# ior7f701503 register map
Registers are 8-bit, access not given, no defined reset value unless marked. A register's access mark holds for its fields unless they carry their own. Addresses are absolute; registers are grouped by the start of their names; [hi:lo] are bit positions; {n}, {i} and the like mark numbered series.

## SFR (part 3 of 4)
0xFFD0903C RSCAN1TMDF13 32-bit
0xFFD0903C RSCAN1TMDF13L 16-bit
0xFFD0903C RSCAN1TMDF13LL
0xFFD0903D RSCAN1TMDF13LH
0xFFD0903E RSCAN1TMDF13H 16-bit
0xFFD0903E RSCAN1TMDF13HL
0xFFD0903F RSCAN1TMDF13HH
0xFFD0904C RSCAN1TMDF14 32-bit
0xFFD0904C RSCAN1TMDF14L 16-bit
0xFFD0904C RSCAN1TMDF14LL
0xFFD0904D RSCAN1TMDF14LH
0xFFD0904E RSCAN1TMDF14H 16-bit
0xFFD0904E RSCAN1TMDF14HL
0xFFD0904F RSCAN1TMDF14HH
0xFFD0905C RSCAN1TMDF15 32-bit
0xFFD0905C RSCAN1TMDF15L 16-bit
0xFFD0905C RSCAN1TMDF15LL
0xFFD0905D RSCAN1TMDF15LH
0xFFD0905E RSCAN1TMDF15H 16-bit
0xFFD0905E RSCAN1TMDF15HL
0xFFD0905F RSCAN1TMDF15HH
{0xFFD08F6C+0x10*i} RSCAN1TMDF{i} 32-bit (i=16..19)
{0xFFD08F6C+0x10*i} RSCAN1TMDF{i}L 16-bit (i=16..19)
{0xFFD08F6C+0x10*i} RSCAN1TMDF{i}LL (i=16..19)
{0xFFD08F6D+0x10*i} RSCAN1TMDF{i}LH (i=16..19)
{0xFFD08F6E+0x10*i} RSCAN1TMDF{i}H 16-bit (i=16..19)
{0xFFD08F6E+0x10*i} RSCAN1TMDF{i}HL (i=16..19)
{0xFFD08F6F+0x10*i} RSCAN1TMDF{i}HH (i=16..19)
{0xFFD09008+0x10*i} RSCAN1TMDF{i:03} 32-bit (i=10..12)
{0xFFD09008+0x10*i} RSCAN1TMDF{i:03}L 16-bit (i=10..12)
{0xFFD09008+0x10*i} RSCAN1TMDF{i:03}LL (i=10..12)
{0xFFD09009+0x10*i} RSCAN1TMDF{i:03}LH (i=10..12)
{0xFFD0900A+0x10*i} RSCAN1TMDF{i:03}H 16-bit (i=10..12)
{0xFFD0900A+0x10*i} RSCAN1TMDF{i:03}HL (i=10..12)
{0xFFD0900B+0x10*i} RSCAN1TMDF{i:03}HH (i=10..12)
{0xFFD089CC+0x10*i} RSCAN1TMDF{i} 32-bit (i=110..115)
{0xFFD089CC+0x10*i} RSCAN1TMDF{i}L 16-bit (i=110..115)
{0xFFD089CC+0x10*i} RSCAN1TMDF{i}LL (i=110..115)
{0xFFD089CD+0x10*i} RSCAN1TMDF{i}LH (i=110..115)
{0xFFD089CE+0x10*i} RSCAN1TMDF{i}H 16-bit (i=110..115)
{0xFFD089CE+0x10*i} RSCAN1TMDF{i}HL (i=110..115)
{0xFFD089CF+0x10*i} RSCAN1TMDF{i}HH (i=110..115)
0xFFD090D8 RSCAN1TMDF013 32-bit
0xFFD090D8 RSCAN1TMDF013L 16-bit
0xFFD090D8 RSCAN1TMDF013LL
0xFFD090D9 RSCAN1TMDF013LH
0xFFD090DA RSCAN1TMDF013H 16-bit
0xFFD090DA RSCAN1TMDF013HL
0xFFD090DB RSCAN1TMDF013HH
0xFFD090E8 RSCAN1TMDF014 32-bit
0xFFD090E8 RSCAN1TMDF014L 16-bit
0xFFD090E8 RSCAN1TMDF014LL
0xFFD090E9 RSCAN1TMDF014LH
0xFFD090EA RSCAN1TMDF014H 16-bit
0xFFD090EA RSCAN1TMDF014HL
0xFFD090EB RSCAN1TMDF014HH
0xFFD090F8 RSCAN1TMDF015 32-bit
0xFFD090F8 RSCAN1TMDF015L 16-bit
0xFFD090F8 RSCAN1TMDF015LL
0xFFD090F9 RSCAN1TMDF015LH
0xFFD090FA RSCAN1TMDF015H 16-bit
0xFFD090FA RSCAN1TMDF015HL
0xFFD090FB RSCAN1TMDF015HH
0xFFD09800 RSCAN1THLACC6 32-bit ro
0xFFD09800 RSCAN1THLACC6L 16-bit ro
0xFFD09800 RSCAN1THLACC6LL ro
0xFFD09801 RSCAN1THLACC6LH ro
{0xFFD09900+4i} RSCAN1RPGACC{i} 32-bit (i=0..63)
{0xFFD09900+4i} RSCAN1RPGACC{i}L 16-bit (i=0..63)
{0xFFD09900+4i} RSCAN1RPGACC{i}LL (i=0..63)
{0xFFD09901+4i} RSCAN1RPGACC{i}LH (i=0..63)
{0xFFD09902+4i} RSCAN1RPGACC{i}H 16-bit (i=0..63)
{0xFFD09902+4i} RSCAN1RPGACC{i}HL (i=0..63)
{0xFFD09903+4i} RSCAN1RPGACC{i}HH (i=0..63)
{0xFFD6D000+4i} ADCA1VCR{i:02} 32-bit (i=0..23)
{0xFFD6D000+4i} ADCA1VCR{i:02}L 16-bit (i=0..23)
{0xFFD6D000+4i} ADCA1VCR{i:02}LL (i=0..23)
{0xFFD6D001+4i} ADCA1VCR{i:02}LH (i=0..23)
0xFFD6D0F4 ADCA1PWDVCR 32-bit ro
0xFFD6D0F4 ADCA1PWDVCRL 16-bit ro
0xFFD6D0F4 ADCA1PWDVCRLL ro
0xFFD6D0F5 ADCA1PWDVCRLH ro
0xFFD6D100 ADCA1DR00 32-bit ro
0xFFD6D100 ADCA1DR00L 16-bit ro
0xFFD6D102 ADCA1DR00H 16-bit ro
0xFFD6D104 ADCA1DR02 32-bit ro
0xFFD6D104 ADCA1DR02L 16-bit ro
0xFFD6D106 ADCA1DR02H 16-bit ro
0xFFD6D108 ADCA1DR04 32-bit ro
0xFFD6D108 ADCA1DR04L 16-bit ro
0xFFD6D10A ADCA1DR04H 16-bit ro
0xFFD6D10C ADCA1DR06 32-bit ro
0xFFD6D10C ADCA1DR06L 16-bit ro
0xFFD6D10E ADCA1DR06H 16-bit ro
0xFFD6D110 ADCA1DR08 32-bit ro
0xFFD6D110 ADCA1DR08L 16-bit ro
0xFFD6D112 ADCA1DR08H 16-bit ro
0xFFD6D114 ADCA1DR10 32-bit ro
0xFFD6D114 ADCA1DR10L 16-bit ro
0xFFD6D116 ADCA1DR10H 16-bit ro
0xFFD6D118 ADCA1DR12 32-bit ro
0xFFD6D118 ADCA1DR12L 16-bit ro
0xFFD6D11A ADCA1DR12H 16-bit ro
0xFFD6D11C ADCA1DR14 32-bit ro
0xFFD6D11C ADCA1DR14L 16-bit ro
0xFFD6D11E ADCA1DR14H 16-bit ro
0xFFD6D120 ADCA1DR16 32-bit ro
0xFFD6D120 ADCA1DR16L 16-bit ro
0xFFD6D122 ADCA1DR16H 16-bit ro
0xFFD6D124 ADCA1DR18 32-bit ro
0xFFD6D124 ADCA1DR18L 16-bit ro
0xFFD6D126 ADCA1DR18H 16-bit ro
0xFFD6D128 ADCA1DR20 32-bit ro
0xFFD6D128 ADCA1DR20L 16-bit ro
0xFFD6D12A ADCA1DR20H 16-bit ro
0xFFD6D12C ADCA1DR22 32-bit ro
0xFFD6D12C ADCA1DR22L 16-bit ro
0xFFD6D12E ADCA1DR22H 16-bit ro
0xFFD6D178 ADCA1PWDTSNDR 32-bit ro
0xFFD6D17A ADCA1PWDTSNDRH 16-bit ro
{0xFFD6D200+4i} ADCA1DIR{i:02} 32-bit ro (i=0..23)
0xFFD6D2F4 ADCA1PWDDIR 32-bit ro
0xFFD6D300 ADCA1ADHALTR 32-bit wo
0xFFD6D300 ADCA1ADHALTRL 16-bit wo
0xFFD6D300 ADCA1ADHALTRLL wo
0xFFD6D304 ADCA1ADCR 32-bit
0xFFD6D304 ADCA1ADCRL 16-bit
0xFFD6D304 ADCA1ADCRLL
0xFFD6D308 ADCA1SGSTR 32-bit ro
0xFFD6D308 ADCA1SGSTRL 16-bit ro
0xFFD6D334 ADCA1SFTCR 32-bit
0xFFD6D334 ADCA1SFTCRL 16-bit
0xFFD6D334 ADCA1SFTCRLL
{0xFFD6D338+4i} ADCA1ULLMTBR{i} 32-bit (i=0..2)
{0xFFD6D338+4i} ADCA1ULLMTBR{i}L 16-bit (i=0..2)
{0xFFD6D33A+4i} ADCA1ULLMTBR{i}H 16-bit (i=0..2)
0xFFD6D344 ADCA1ECR 32-bit wo
0xFFD6D344 ADCA1ECRL 16-bit wo
0xFFD6D344 ADCA1ECRLL wo
0xFFD6D348 ADCA1ULER 32-bit ro
0xFFD6D348 ADCA1ULERL 16-bit ro
0xFFD6D348 ADCA1ULERLL ro
0xFFD6D349 ADCA1ULERLH ro
0xFFD6D34C ADCA1OWER 32-bit ro
0xFFD6D34C ADCA1OWERL 16-bit ro
0xFFD6D34C ADCA1OWERLL ro
0xFFD6D350 ADCA1DGCTL0 32-bit
0xFFD6D350 ADCA1DGCTL0L 16-bit
0xFFD6D350 ADCA1DGCTL0LL
0xFFD6D354 ADCA1DGCTL1 32-bit
0xFFD6D354 ADCA1DGCTL1L 16-bit
0xFFD6D358 ADCA1PDCTL1 32-bit
0xFFD6D358 ADCA1PDCTL1L 16-bit
0xFFD6D35C ADCA1PDCTL2 32-bit
0xFFD6D35C ADCA1PDCTL2L 16-bit
0xFFD6D35C ADCA1PDCTL2LL
0xFFD6D380 ADCA1SMPCR 32-bit
0xFFD6D380 ADCA1SMPCRL 16-bit
0xFFD6D380 ADCA1SMPCRLL
0xFFD6D388 ADCA1EMU
{0xFFD6D400+0x40*i} ADCA1SGSTCR{i} 32-bit wo (i=1..3)
{0xFFD6D400+0x40*i} ADCA1SGSTCR{i}L 16-bit wo (i=1..3)
{0xFFD6D400+0x40*i} ADCA1SGSTCR{i}LL wo (i=1..3)
{0xFFD6D408+0x40*i} ADCA1SGCR{i} 32-bit (i=1..3)
{0xFFD6D408+0x40*i} ADCA1SGCR{i}L 16-bit (i=1..3)
{0xFFD6D408+0x40*i} ADCA1SGCR{i}LL (i=1..3)
{0xFFD6D40C+0x40*i} ADCA1SGVCSP{i} 32-bit (i=1..3)
{0xFFD6D40C+0x40*i} ADCA1SGVCSP{i}L 16-bit (i=1..3)
{0xFFD6D40C+0x40*i} ADCA1SGVCSP{i}LL (i=1..3)
{0xFFD6D410+0x40*i} ADCA1SGVCEP{i} 32-bit (i=1..3)
{0xFFD6D410+0x40*i} ADCA1SGVCEP{i}L 16-bit (i=1..3)
{0xFFD6D410+0x40*i} ADCA1SGVCEP{i}LL (i=1..3)
{0xFFD6D414+0x40*i} ADCA1SGMCYCR{i} 32-bit (i=1..3)
{0xFFD6D414+0x40*i} ADCA1SGMCYCR{i}L 16-bit (i=1..3)
{0xFFD6D414+0x40*i} ADCA1SGMCYCR{i}LL (i=1..3)
{0xFFD6D418+0x40*i} ADCA1SGSEFCR{i} 32-bit wo (i=1..3)
{0xFFD6D418+0x40*i} ADCA1SGSEFCR{i}L 16-bit wo (i=1..3)
{0xFFD6D418+0x40*i} ADCA1SGSEFCR{i}LL wo (i=1..3)
{0xFFD6D41C+0x40*i} ADCA1SGTSEL{i} 32-bit (i=1..3)
{0xFFD6D41C+0x40*i} ADCA1SGTSEL{i}L 16-bit (i=1..3)
0xFFD6D508 ADCA1PWDSGCR 32-bit
0xFFD6D508 ADCA1PWDSGCRL 16-bit
0xFFD6D508 ADCA1PWDSGCRLL
0xFFD6D518 ADCA1PWDSGSEFCR 32-bit wo
0xFFD6D518 ADCA1PWDSGSEFCRL 16-bit wo
0xFFD6D518 ADCA1PWDSGSEFCRLL wo
0xFFD6E000 ETNB0CCC 32-bit
0xFFD6E000 ETNB0CCCL 16-bit
0xFFD6E000 ETNB0CCCLL
0xFFD6E001 ETNB0CCCLH
0xFFD6E002 ETNB0CCCH 16-bit
0xFFD6E002 ETNB0CCCHL
0xFFD6E003 ETNB0CCCHH
0xFFD6E004 ETNB0DBAT 32-bit
0xFFD6E008 ETNB0DLR 32-bit
0xFFD6E00C ETNB0CSR 32-bit ro
{0xFFD6E010+4i} ETNB0CDAR{i} 32-bit ro (i=0..21)
0xFFD6E088 ETNB0ESR 32-bit ro
0xFFD6E090 ETNB0RCR 32-bit
{0xFFD6E094+4i} ETNB0RQC{i} 32-bit (i=0..4)
{0xFFD6E094+4i} ETNB0RQC{i}L 16-bit (i=0..4)
{0xFFD6E094+4i} ETNB0RQC{i}LL (i=0..4)
{0xFFD6E095+4i} ETNB0RQC{i}LH (i=0..4)
{0xFFD6E096+4i} ETNB0RQC{i}H 16-bit (i=0..4)
{0xFFD6E096+4i} ETNB0RQC{i}HL (i=0..4)
{0xFFD6E097+4i} ETNB0RQC{i}HH (i=0..4)
0xFFD6E0B0 ETNB0RPC 32-bit
0xFFD6E0BC ETNB0UFCW 32-bit
0xFFD6E0C0 ETNB0UFCS 32-bit
{0xFFD6E0C4+4i} ETNB0UFCV{i} 32-bit ro (i=0..4)
{0xFFD6E0E0+4i} ETNB0UFCD{i} 32-bit (i=0..4)
{0xFFD6E0E0+4i} ETNB0UFCD{i}L 16-bit (i=0..4)
{0xFFD6E0E0+4i} ETNB0UFCD{i}LL (i=0..4)
{0xFFD6E0E1+4i} ETNB0UFCD{i}LH (i=0..4)
{0xFFD6E0E2+4i} ETNB0UFCD{i}H 16-bit (i=0..4)
{0xFFD6E0E2+4i} ETNB0UFCD{i}HL (i=0..4)
{0xFFD6E0E3+4i} ETNB0UFCD{i}HH (i=0..4)
0xFFD6E0FC ETNB0SFO 32-bit
{0xFFD6E100+4i} ETNB0SFP{i} 32-bit (i=0..31)
0xFFD6E1C0 ETNB0SFM0 32-bit
0xFFD6E1C4 ETNB0SFM1 32-bit
0xFFD6E300 ETNB0TGC 32-bit
0xFFD6E304 ETNB0TCCR 32-bit
0xFFD6E304 ETNB0TCCRL 16-bit
0xFFD6E304 ETNB0TCCRLL
0xFFD6E305 ETNB0TCCRLH
0xFFD6E306 ETNB0TCCRH 16-bit
0xFFD6E306 ETNB0TCCRHL
0xFFD6E308 ETNB0TSR 32-bit ro
{0xFFD6E310+4i} ETNB0TFA{i} 32-bit ro (i=0..2)
0xFFD6E320 ETNB0CIVR0 32-bit
0xFFD6E324 ETNB0CIVR1 32-bit
0xFFD6E328 ETNB0CDVR0 32-bit
0xFFD6E32C ETNB0CDVR1 32-bit
0xFFD6E330 ETNB0CUL0 32-bit
0xFFD6E334 ETNB0CUL1 32-bit
0xFFD6E338 ETNB0CLL0 32-bit
0xFFD6E33C ETNB0CLL1 32-bit
0xFFD6E350 ETNB0DIC 32-bit
0xFFD6E354 ETNB0DIS 32-bit
0xFFD6E358 ETNB0EIC 32-bit
0xFFD6E35C ETNB0EIS 32-bit
{0xFFD6E360+8i} ETNB0RIC{i} 32-bit (i=0..2)
{0xFFD6E364+8i} ETNB0RIS{i} 32-bit (i=0..2)
0xFFD6E378 ETNB0TIC 32-bit
0xFFD6E37C ETNB0TIS 32-bit
0xFFD6E380 ETNB0ISS 32-bit ro
0xFFD6E390 ETNB0GCCR 32-bit
0xFFD6E390 ETNB0GCCRL 16-bit
0xFFD6E390 ETNB0GCCRLL
0xFFD6E391 ETNB0GCCRLH
0xFFD6E394 ETNB0GMTT 32-bit
0xFFD6E398 ETNB0GPTC 32-bit
0xFFD6E39C ETNB0GTI 32-bit
{0xFFD6E3A0+4i} ETNB0GTO{i} 32-bit (i=0..2)
0xFFD6E3AC ETNB0GIC 32-bit
0xFFD6E3B0 ETNB0GIS 32-bit
0xFFD6E3B4 ETNB0GCPT 32-bit ro
{0xFFD6E3B8+4i} ETNB0GCT{i} 32-bit ro (i=0..2)
0xFFD6E500 ETNB0ECMR 32-bit
0xFFD6E508 ETNB0RFLR 32-bit
0xFFD6E510 ETNB0ECSR 32-bit
0xFFD6E518 ETNB0ECSIPR 32-bit
0xFFD6E520 ETNB0PIR 32-bit
0xFFD6E528 ETNB0PLSR 32-bit ro
0xFFD6E554 ETNB0APFTP 32-bit
0xFFD6E558 ETNB0MPR 32-bit
0xFFD6E55C ETNB0PFTCR 32-bit
0xFFD6E560 ETNB0PFRCR 32-bit
0xFFD6E5B0 ETNB0GECMR 32-bit
0xFFD6E5C0 ETNB0MAHR 32-bit
0xFFD6E5C8 ETNB0MALR 32-bit
0xFFD6E700 ETNB0TROCR 32-bit
0xFFD6E708 ETNB0CDCR 32-bit
0xFFD6E710 ETNB0LCCR 32-bit
0xFFD6E740 ETNB0CEFCR 32-bit
0xFFD6E748 ETNB0FRECR 32-bit
0xFFD6E750 ETNB0TSFRCR 32-bit
0xFFD6E758 ETNB0TLFRCR 32-bit
0xFFD6E760 ETNB0RFCR 32-bit
0xFFD6E768 ETNB0CERCR 32-bit
0xFFD6E770 ETNB0CEECR 32-bit
0xFFD6E778 ETNB0MAFCR 32-bit
0xFFD6F000 ETNB0IFCTL 32-bit
{0xFFD70000+0x100*i} OSTM{i}CMP 32-bit (i=0..4)
{0xFFD70004+0x100*i} OSTM{i}CNT 32-bit ro (i=0..4)
{0xFFD70010+0x100*i} OSTM{i}TE ro (i=0..4)
{0xFFD70014+0x100*i} OSTM{i}TS wo (i=0..4)
{0xFFD70018+0x100*i} OSTM{i}TT wo (i=0..4)
{0xFFD70020+0x100*i} OSTM{i}CTL (i=0..4)
{0xFFD70024+0x100*i} OSTM{i}EMU (i=0..4)
{0xFFD70B00+0x100*i} OSTM{i}CMP 32-bit (i=5..9)
{0xFFD70B04+0x100*i} OSTM{i}CNT 32-bit ro (i=5..9)
{0xFFD70B10+0x100*i} OSTM{i}TE ro (i=5..9)
{0xFFD70B14+0x100*i} OSTM{i}TS wo (i=5..9)
{0xFFD70B18+0x100*i} OSTM{i}TT wo (i=5..9)
{0xFFD70B20+0x100*i} OSTM{i}CTL (i=5..9)
{0xFFD70B24+0x100*i} OSTM{i}EMU (i=5..9)
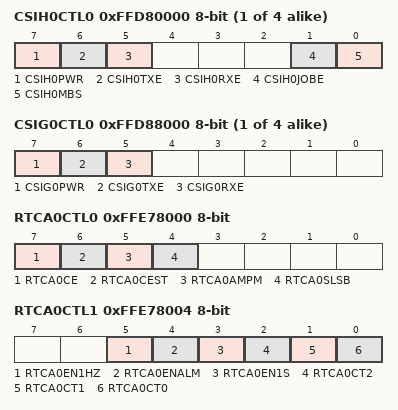
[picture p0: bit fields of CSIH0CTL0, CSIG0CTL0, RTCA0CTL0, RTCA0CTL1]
{0xFFD80000+0x2000*i} CSIH{i}CTL0 (i=0..3)
  [7] CSIH{i}PWR, [6] CSIH{i}TXE, [5] CSIH{i}RXE, [1] CSIH{i}JOBE, [0] CSIH{i}MBS
{0xFFD80004+0x2000*i} CSIH{i}STR0 32-bit ro (i=0..3)
{0xFFD80008+0x2000*i} CSIH{i}STCR0 16-bit (i=0..3)
{0xFFD80010+0x2000*i} CSIH{i}CTL1 32-bit (i=0..3)
{0xFFD80014+0x2000*i} CSIH{i}CTL2 16-bit (i=0..3)
{0xFFD80018+0x2000*i} CSIH{i}EMU (i=0..3)
  [7] CSIH{i}SVSDIS
{0xFFD81000+0x2000*i} CSIH{i}MCTL1 32-bit (i=0..3)
{0xFFD81004+0x2000*i} CSIH{i}MCTL2 32-bit (i=0..3)
{0xFFD81008+0x2000*i} CSIH{i}TX0W 32-bit (i=0..3)
{0xFFD8100C+0x2000*i} CSIH{i}TX0H 16-bit (i=0..3)
{0xFFD81010+0x2000*i} CSIH{i}RX0W 32-bit ro (i=0..3)
{0xFFD81014+0x2000*i} CSIH{i}RX0H 16-bit ro (i=0..3)
{0xFFD81018+0x2000*i} CSIH{i}MRWP0 32-bit (i=0..3)
{0xFFD81040+0x2000*i} CSIH{i}MCTL0 16-bit (i=0..3)
{0xFFD81044+4i} CSIH0CFG{i} 32-bit (i=0..7)
{0xFFD81068+0x2000*i} CSIH{i}BRS0 16-bit (i=0..3)
{0xFFD8106C+0x2000*i} CSIH{i}BRS1 16-bit (i=0..3)
{0xFFD81070+0x2000*i} CSIH{i}BRS2 16-bit (i=0..3)
{0xFFD81074+0x2000*i} CSIH{i}BRS3 16-bit (i=0..3)
{0xFFD83044+4i} CSIH1CFG{i} 32-bit (i=0..5)
{0xFFD85044+4i} CSIH2CFG{i} 32-bit (i=0..5)
{0xFFD87044+4i} CSIH3CFG{i} 32-bit (i=0..3)
{0xFFD88000+0x2000*i} CSIG{i}CTL0 (i=0..3)
  [7] CSIG{i}PWR, [6] CSIG{i}TXE, [5] CSIG{i}RXE
{0xFFD88004+0x2000*i} CSIG{i}STR0 32-bit ro (i=0..3)
{0xFFD88008+0x2000*i} CSIG{i}STCR0 16-bit (i=0..3)
{0xFFD88010+0x2000*i} CSIG{i}CTL1 32-bit (i=0..3)
{0xFFD88014+0x2000*i} CSIG{i}CTL2 16-bit (i=0..3)
{0xFFD88018+0x2000*i} CSIG{i}EMU (i=0..3)
  [7] CSIG{i}SVSDIS
{0xFFD89000+0x2000*i} CSIG{i}BCTL0 (i=0..3)
  [0] CSIG{i}SCE
{0xFFD89004+0x2000*i} CSIG{i}TX0W 32-bit (i=0..3)
{0xFFD89008+0x2000*i} CSIG{i}TX0H 16-bit (i=0..3)
{0xFFD8900C+0x2000*i} CSIG{i}RX0 16-bit ro (i=0..3)
{0xFFD89010+0x2000*i} CSIG{i}CFG0 32-bit (i=0..3)
0xFFDD0004 PIC0SST wo
0xFFDD0010 PIC0SSER0 16-bit
0xFFDD0018 PIC0SSER2 16-bit
0xFFDD0080 PIC0HIZCEN0
{0xFFDCFA50+4i} PIC0ADTEN{i} 16-bit (i=400..402)
{0xFFDCFDA0+4i} PIC0REG{i} 32-bit (i=200..203)
0xFFDD00E8 PIC0REG30 32-bit
0xFFDD00EC PIC0REG31 32-bit
{0xFFDDD000+4i} FSGD02PROT{i} 32-bit (i=0..10)
{0xFFDDD000+4i} FSGD02PROT{i}L 16-bit (i=0..10)
{0xFFDDD000+4i} FSGD02PROT{i}LL (i=0..10)
{0xFFDDD001+4i} FSGD02PROT{i}LH (i=0..10)
{0xFFDDD002+4i} FSGD02PROT{i}H 16-bit (i=0..10)
{0xFFDDD002+4i} FSGD02PROT{i}HL (i=0..10)
{0xFFDDD003+4i} FSGD02PROT{i}HH (i=0..10)
0xFFDDD040 ERRSLV02CTL 32-bit wo
0xFFDDD040 ERRSLV02CTLL 16-bit wo
0xFFDDD040 ERRSLV02CTLLL wo
0xFFDDD044 ERRSLV02STAT 32-bit ro
0xFFDDD044 ERRSLV02STATL 16-bit ro
0xFFDDD044 ERRSLV02STATLL ro
0xFFDDD04C ERRSLV02TYPE 32-bit ro
0xFFDDD04C ERRSLV02TYPEL 16-bit ro
{0xFFE20000+4i} TAUD0CDR{i} 16-bit (i=0..15)
0xFFE20040 TAUD0TOL 16-bit
0xFFE20044 TAUD0RDT 16-bit wo
0xFFE20048 TAUD0RSF 16-bit ro
0xFFE2004C TAUD0TRO 16-bit
0xFFE20050 TAUD0TME 16-bit
0xFFE20054 TAUD0TDL 16-bit
0xFFE20058 TAUD0TO 16-bit
0xFFE2005C TAUD0TOE 16-bit
{0xFFE20080+4i} TAUD0CNT{i} 16-bit ro (i=0..15)
{0xFFE200C0+4i} TAUD0CMUR{i} (i=0..15)
{0xFFE20140+4i} TAUD0CSR{i} ro (i=0..15)
{0xFFE20180+4i} TAUD0CSC{i} wo (i=0..15)
0xFFE201C0 TAUD0TE 16-bit ro
0xFFE201C4 TAUD0TS 16-bit wo
0xFFE201C8 TAUD0TT 16-bit wo
{0xFFE20200+4i} TAUD0CMOR{i} 16-bit (i=0..15)
0xFFE20240 TAUD0TPS 16-bit
0xFFE20244 TAUD0BRS
0xFFE20248 TAUD0TOM 16-bit
0xFFE2024C TAUD0TOC 16-bit
0xFFE20250 TAUD0TDE 16-bit
0xFFE20254 TAUD0TDM 16-bit
0xFFE20258 TAUD0TRE 16-bit
0xFFE2025C TAUD0TRC 16-bit
0xFFE20260 TAUD0RDE 16-bit
0xFFE20264 TAUD0RDM 16-bit
0xFFE20268 TAUD0RDS 16-bit
0xFFE2026C TAUD0RDC 16-bit
0xFFE20290 TAUD0EMU
{0xFFE30000+4i} TAUB0CDR{i} 16-bit (i=0..15)
0xFFE30040 TAUB0TOL 16-bit
0xFFE30044 TAUB0RDT 16-bit wo
0xFFE30048 TAUB0RSF 16-bit ro
0xFFE30054 TAUB0TDL 16-bit
0xFFE30058 TAUB0TO 16-bit
0xFFE3005C TAUB0TOE 16-bit
{0xFFE30080+4i} TAUB0CNT{i} 16-bit ro (i=0..15)
{0xFFE300C0+4i} TAUB0CMUR{i} (i=0..15)
{0xFFE30140+4i} TAUB0CSR{i} ro (i=0..15)
{0xFFE30180+4i} TAUB0CSC{i} wo (i=0..15)
0xFFE301C0 TAUB0TE 16-bit ro
0xFFE301C4 TAUB0TS 16-bit wo
0xFFE301C8 TAUB0TT 16-bit wo
{0xFFE30200+4i} TAUB0CMOR{i} 16-bit (i=0..15)
0xFFE30240 TAUB0TPS 16-bit
0xFFE30248 TAUB0TOM 16-bit
0xFFE3024C TAUB0TOC 16-bit
0xFFE30250 TAUB0TDE 16-bit
0xFFE30260 TAUB0RDE 16-bit
0xFFE30264 TAUB0RDM 16-bit
0xFFE30268 TAUB0RDS 16-bit
0xFFE3026C TAUB0RDC 16-bit
0xFFE30290 TAUB0EMU
{0xFFE31000+4i} TAUB1CDR{i} 16-bit (i=0..15)
0xFFE31040 TAUB1TOL 16-bit
0xFFE31044 TAUB1RDT 16-bit wo
0xFFE31048 TAUB1RSF 16-bit ro
0xFFE31054 TAUB1TDL 16-bit
0xFFE31058 TAUB1TO 16-bit
0xFFE3105C TAUB1TOE 16-bit
{0xFFE31080+4i} TAUB1CNT{i} 16-bit ro (i=0..15)
{0xFFE310C0+4i} TAUB1CMUR{i} (i=0..15)
{0xFFE31140+4i} TAUB1CSR{i} ro (i=0..15)
{0xFFE31180+4i} TAUB1CSC{i} wo (i=0..15)
0xFFE311C0 TAUB1TE 16-bit ro
0xFFE311C4 TAUB1TS 16-bit wo
0xFFE311C8 TAUB1TT 16-bit wo
{0xFFE31200+4i} TAUB1CMOR{i} 16-bit (i=0..15)
0xFFE31240 TAUB1TPS 16-bit
0xFFE31248 TAUB1TOM 16-bit
0xFFE3124C TAUB1TOC 16-bit
0xFFE31250 TAUB1TDE 16-bit
0xFFE31260 TAUB1RDE 16-bit
0xFFE31264 TAUB1RDM 16-bit
0xFFE31268 TAUB1RDS 16-bit
0xFFE3126C TAUB1RDC 16-bit
0xFFE31290 TAUB1EMU
{0xFFE50000+4i} TAUJ0CDR{i} 32-bit (i=0..3)
{0xFFE50010+4i} TAUJ0CNT{i} 32-bit ro (i=0..3)
{0xFFE50020+4i} TAUJ0CMUR{i} (i=0..3)
{0xFFE50030+4i} TAUJ0CSR{i} ro (i=0..3)
{0xFFE50040+4i} TAUJ0CSC{i} wo (i=0..3)
0xFFE50050 TAUJ0TE ro
0xFFE50054 TAUJ0TS wo
0xFFE50058 TAUJ0TT wo
0xFFE5005C TAUJ0TO
0xFFE50060 TAUJ0TOE
0xFFE50064 TAUJ0TOL
0xFFE50068 TAUJ0RDT wo
0xFFE5006C TAUJ0RSF ro
{0xFFE50080+4i} TAUJ0CMOR{i} 16-bit (i=0..3)
0xFFE50090 TAUJ0TPS 16-bit
0xFFE50094 TAUJ0BRS
0xFFE50098 TAUJ0TOM
0xFFE5009C TAUJ0TOC
0xFFE500A0 TAUJ0RDE
0xFFE500A4 TAUJ0RDM
0xFFE500A8 TAUJ0EMU
{0xFFE51000+4i} TAUJ1CDR{i} 32-bit (i=0..3)
{0xFFE51010+4i} TAUJ1CNT{i} 32-bit ro (i=0..3)
{0xFFE51020+4i} TAUJ1CMUR{i} (i=0..3)
{0xFFE51030+4i} TAUJ1CSR{i} ro (i=0..3)
{0xFFE51040+4i} TAUJ1CSC{i} wo (i=0..3)
0xFFE51050 TAUJ1TE ro
0xFFE51054 TAUJ1TS wo
0xFFE51058 TAUJ1TT wo
0xFFE5105C TAUJ1TO
0xFFE51060 TAUJ1TOE
0xFFE51064 TAUJ1TOL
0xFFE51068 TAUJ1RDT wo
0xFFE5106C TAUJ1RSF ro
{0xFFE51080+4i} TAUJ1CMOR{i} 16-bit (i=0..3)
0xFFE51090 TAUJ1TPS 16-bit
0xFFE51094 TAUJ1BRS
0xFFE51098 TAUJ1TOM
0xFFE5109C TAUJ1TOC
0xFFE510A0 TAUJ1RDE
0xFFE510A4 TAUJ1RDM
0xFFE510A8 TAUJ1EMU
0xFFE70000 PWSA0CTL
0xFFE70004 PWSA0STR ro
0xFFE70008 PWSA0STC wo
0xFFE7000C PWSA0EMU
{0xFFE70020+4i} PWSA0QUE{i} ro (i=0..7)
0xFFE70040 PWSA0PVCR00_01 32-bit
0xFFE70044 PWSA0PVCR02_03 32-bit
0xFFE70048 PWSA0PVCR04_05 32-bit
0xFFE7004C PWSA0PVCR06_07 32-bit
0xFFE70050 PWSA0PVCR08_09 32-bit
0xFFE70054 PWSA0PVCR10_11 32-bit
0xFFE70058 PWSA0PVCR12_13 32-bit
0xFFE7005C PWSA0PVCR14_15 32-bit
0xFFE70060 PWSA0PVCR16_17 32-bit
0xFFE70064 PWSA0PVCR18_19 32-bit
0xFFE70068 PWSA0PVCR20_21 32-bit
0xFFE7006C PWSA0PVCR22_23 32-bit
0xFFE70070 PWSA0PVCR24_25 32-bit
0xFFE70074 PWSA0PVCR26_27 32-bit
0xFFE70078 PWSA0PVCR28_29 32-bit
0xFFE7007C PWSA0PVCR30_31 32-bit
0xFFE70080 PWSA0PVCR32_33 32-bit
0xFFE70084 PWSA0PVCR34_35 32-bit
0xFFE70088 PWSA0PVCR36_37 32-bit
0xFFE7008C PWSA0PVCR38_39 32-bit
0xFFE70090 PWSA0PVCR40_41 32-bit
0xFFE70094 PWSA0PVCR42_43 32-bit
0xFFE70098 PWSA0PVCR44_45 32-bit
0xFFE7009C PWSA0PVCR46_47 32-bit
0xFFE700A0 PWSA0PVCR48_49 32-bit
0xFFE700A4 PWSA0PVCR50_51 32-bit
0xFFE700A8 PWSA0PVCR52_53 32-bit
0xFFE700AC PWSA0PVCR54_55 32-bit
0xFFE700B0 PWSA0PVCR56_57 32-bit
0xFFE700B4 PWSA0PVCR58_59 32-bit
0xFFE700B8 PWSA0PVCR60_61 32-bit
0xFFE700BC PWSA0PVCR62_63 32-bit
0xFFE700C0 PWSA0PVCR64_65 32-bit
0xFFE700C4 PWSA0PVCR66_67 32-bit
0xFFE700C8 PWSA0PVCR68_69 32-bit
0xFFE700CC PWSA0PVCR70_71 32-bit
0xFFE700D0 PWSA0PVCR72_73 32-bit
0xFFE700D4 PWSA0PVCR74_75 32-bit
0xFFE700D8 PWSA0PVCR76_77 32-bit
0xFFE700DC PWSA0PVCR78_79 32-bit
0xFFE700E0 PWSA0PVCR80_81 32-bit
0xFFE700E4 PWSA0PVCR82_83 32-bit
0xFFE700E8 PWSA0PVCR84_85 32-bit
0xFFE700EC PWSA0PVCR86_87 32-bit
0xFFE700F0 PWSA0PVCR88_89 32-bit
0xFFE700F4 PWSA0PVCR90_91 32-bit
0xFFE700F8 PWSA0PVCR92_93 32-bit
0xFFE700FC PWSA0PVCR94_95 32-bit
{0xFFE71000+0x40*i} PWGA{i}CSDR 16-bit (i=0..71)
{0xFFE71004+0x40*i} PWGA{i}CRDR 16-bit (i=0..71)
{0xFFE71008+0x40*i} PWGA{i}CTDR 16-bit (i=0..71)
{0xFFE7100C+0x40*i} PWGA{i}RDT wo (i=0..71)
{0xFFE71010+0x40*i} PWGA{i}RSF ro (i=0..71)
{0xFFE71014+0x40*i} PWGA{i}CNT 16-bit ro (i=0..71)
{0xFFE71020+0x40*i} PWGA{i}CTL (i=0..71)
{0xFFE71024+0x40*i} PWGA{i}CSBR 16-bit ro (i=0..71)
{0xFFE71028+0x40*i} PWGA{i}CRBR 16-bit ro (i=0..71)
{0xFFE7102C+0x40*i} PWGA{i}CTBR 16-bit ro (i=0..71)
{0xFFE72800+4i} PWBA0BRS{i} 16-bit (i=0..3)
0xFFE72810 PWBA0TE ro
0xFFE72814 PWBA0TS wo
0xFFE72818 PWBA0TT wo
0xFFE7281C PWBA0EMU
{0xFFE73000+4i} SLPWGA{i} 32-bit (i=0..2)
0xFFE78000 RTCA0CTL0
  [7] RTCA0CE, [6] RTCA0CEST ro, [5] RTCA0AMPM, [4] RTCA0SLSB
0xFFE78004 RTCA0CTL1
  [5] RTCA0EN1HZ, [4] RTCA0ENALM, [3] RTCA0EN1S, [2] RTCA0CT2, [1] RTCA0CT1, [0] RTCA0CT0
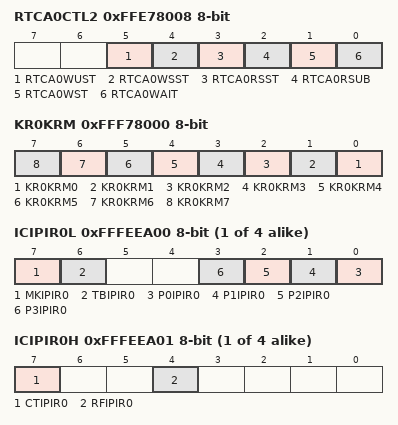
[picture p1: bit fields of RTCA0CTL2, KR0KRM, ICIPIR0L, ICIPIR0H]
0xFFE78008 RTCA0CTL2
  [5] RTCA0WUST ro, [4] RTCA0WSST ro, [3] RTCA0RSST ro, [2] RTCA0RSUB, [1] RTCA0WST ro, [0] RTCA0WAIT
0xFFE7800C RTCA0SUBC 32-bit ro
0xFFE78010 RTCA0SRBU 32-bit ro
0xFFE78014 RTCA0SEC
0xFFE78018 RTCA0MIN
0xFFE7801C RTCA0HOUR
0xFFE78020 RTCA0WEEK
0xFFE78024 RTCA0DAY
0xFFE78028 RTCA0MONTH
0xFFE7802C RTCA0YEAR
0xFFE78030 RTCA0TIME 32-bit
0xFFE78034 RTCA0CAL 32-bit
0xFFE78038 RTCA0SUBU
0xFFE7803C RTCA0SCMP 32-bit
0xFFE78040 RTCA0ALM
0xFFE78044 RTCA0ALH
0xFFE78048 RTCA0ALW
0xFFE7804C RTCA0SECC ro
0xFFE78050 RTCA0MINC ro
0xFFE78054 RTCA0HOURC ro
0xFFE78058 RTCA0WEEKC ro
0xFFE7805C RTCA0DAYC ro
0xFFE78060 RTCA0MONC ro
0xFFE78064 RTCA0YEARC ro
0xFFE78068 RTCA0TIMEC 32-bit ro
0xFFE7806C RTCA0CALC 32-bit ro
0xFFE78074 RTCA0EMU
  [7] RTCA0SVSDIS
0xFFE80000 ENCA0CCR0 16-bit
0xFFE80004 ENCA0CCR1 16-bit
0xFFE80008 ENCA0CNT 16-bit
0xFFE8000C ENCA0FLG ro
0xFFE80010 ENCA0FGC wo
0xFFE80014 ENCA0TE ro
0xFFE80018 ENCA0TS wo
0xFFE8001C ENCA0TT wo
0xFFE80020 ENCA0IOC0
0xFFE80040 ENCA0CTL 16-bit
0xFFE80044 ENCA0IOC1
0xFFE80048 ENCA0EMU
0xFFE90000 TAPA0FLG 16-bit ro
0xFFE90004 TAPA0ACWE
0xFFE90008 TAPA0ACTS wo
0xFFE9000C TAPA0ACTT wo
0xFFE90014 TAPA0OPHS wo
0xFFE90018 TAPA0OPHT wo
0xFFE90020 TAPA0CTL0 16-bit
0xFFE90024 TAPA0CTL1
0xFFE90028 TAPA0EMU
{0xFFED0000+0x1000*i} WDTA{i}WDTE (i=0..2)
{0xFFED0004+0x1000*i} WDTA{i}EVAC (i=0..2)
{0xFFED0008+0x1000*i} WDTA{i}REF ro (i=0..2)
{0xFFED000C+0x1000*i} WDTA{i}MD (i=0..2)
{0xFFF20000+4i} ADCA0VCR{i:02} 32-bit (i=0..49)
{0xFFF20000+4i} ADCA0VCR{i:02}L 16-bit (i=0..49)
{0xFFF20000+4i} ADCA0VCR{i:02}LL (i=0..49)
{0xFFF20001+4i} ADCA0VCR{i:02}LH (i=0..49)
0xFFF200F4 ADCA0PWDVCR 32-bit ro
0xFFF200F4 ADCA0PWDVCRL 16-bit ro
0xFFF200F4 ADCA0PWDVCRLL ro
0xFFF200F5 ADCA0PWDVCRLH ro
0xFFF20100 ADCA0DR00 32-bit ro
0xFFF20100 ADCA0DR00L 16-bit ro
0xFFF20102 ADCA0DR00H 16-bit ro
0xFFF20104 ADCA0DR02 32-bit ro
0xFFF20104 ADCA0DR02L 16-bit ro
0xFFF20106 ADCA0DR02H 16-bit ro
0xFFF20108 ADCA0DR04 32-bit ro
0xFFF20108 ADCA0DR04L 16-bit ro
0xFFF2010A ADCA0DR04H 16-bit ro
0xFFF2010C ADCA0DR06 32-bit ro
0xFFF2010C ADCA0DR06L 16-bit ro
0xFFF2010E ADCA0DR06H 16-bit ro
0xFFF20110 ADCA0DR08 32-bit ro
0xFFF20110 ADCA0DR08L 16-bit ro
0xFFF20112 ADCA0DR08H 16-bit ro
0xFFF20114 ADCA0DR10 32-bit ro
0xFFF20114 ADCA0DR10L 16-bit ro
0xFFF20116 ADCA0DR10H 16-bit ro
0xFFF20118 ADCA0DR12 32-bit ro
0xFFF20118 ADCA0DR12L 16-bit ro
0xFFF2011A ADCA0DR12H 16-bit ro
0xFFF2011C ADCA0DR14 32-bit ro
0xFFF2011C ADCA0DR14L 16-bit ro
0xFFF2011E ADCA0DR14H 16-bit ro
0xFFF20120 ADCA0DR16 32-bit ro
0xFFF20120 ADCA0DR16L 16-bit ro
0xFFF20122 ADCA0DR16H 16-bit ro
0xFFF20124 ADCA0DR18 32-bit ro
0xFFF20124 ADCA0DR18L 16-bit ro
0xFFF20126 ADCA0DR18H 16-bit ro
0xFFF20128 ADCA0DR20 32-bit ro
0xFFF20128 ADCA0DR20L 16-bit ro
0xFFF2012A ADCA0DR20H 16-bit ro
0xFFF2012C ADCA0DR22 32-bit ro
0xFFF2012C ADCA0DR22L 16-bit ro
0xFFF2012E ADCA0DR22H 16-bit ro
0xFFF20130 ADCA0DR24 32-bit ro
0xFFF20130 ADCA0DR24L 16-bit ro
0xFFF20132 ADCA0DR24H 16-bit ro
0xFFF20134 ADCA0DR26 32-bit ro
0xFFF20134 ADCA0DR26L 16-bit ro
0xFFF20136 ADCA0DR26H 16-bit ro
0xFFF20138 ADCA0DR28 32-bit ro
0xFFF20138 ADCA0DR28L 16-bit ro
0xFFF2013A ADCA0DR28H 16-bit ro
0xFFF2013C ADCA0DR30 32-bit ro
0xFFF2013C ADCA0DR30L 16-bit ro
0xFFF2013E ADCA0DR30H 16-bit ro
0xFFF20140 ADCA0DR32 32-bit ro
0xFFF20140 ADCA0DR32L 16-bit ro
0xFFF20142 ADCA0DR32H 16-bit ro
0xFFF20144 ADCA0DR34 32-bit ro
0xFFF20144 ADCA0DR34L 16-bit ro
0xFFF20146 ADCA0DR34H 16-bit ro
0xFFF20148 ADCA0DR36 32-bit ro
0xFFF20148 ADCA0DR36L 16-bit ro
0xFFF2014A ADCA0DR36H 16-bit ro
0xFFF2014C ADCA0DR38 32-bit ro
0xFFF2014C ADCA0DR38L 16-bit ro
0xFFF2014E ADCA0DR38H 16-bit ro
0xFFF20150 ADCA0DR40 32-bit ro
0xFFF20150 ADCA0DR40L 16-bit ro
0xFFF20152 ADCA0DR40H 16-bit ro
0xFFF20154 ADCA0DR42 32-bit ro
0xFFF20154 ADCA0DR42L 16-bit ro
0xFFF20156 ADCA0DR42H 16-bit ro
0xFFF20158 ADCA0DR44 32-bit ro
0xFFF20158 ADCA0DR44L 16-bit ro
0xFFF2015A ADCA0DR44H 16-bit ro
0xFFF2015C ADCA0DR46 32-bit ro
0xFFF2015C ADCA0DR46L 16-bit ro
0xFFF2015E ADCA0DR46H 16-bit ro
0xFFF20160 ADCA0DR48 32-bit ro
0xFFF20160 ADCA0DR48L 16-bit ro
0xFFF20162 ADCA0DR48H 16-bit ro
0xFFF20178 ADCA0PWDTSNDR 32-bit ro
0xFFF2017A ADCA0PWDTSNDRH 16-bit ro
{0xFFF20200+4i} ADCA0DIR{i:02} 32-bit ro (i=0..49)
0xFFF202F4 ADCA0PWDDIR 32-bit ro
0xFFF20300 ADCA0ADHALTR 32-bit wo
0xFFF20300 ADCA0ADHALTRL 16-bit wo
0xFFF20300 ADCA0ADHALTRLL wo
0xFFF20304 ADCA0ADCR 32-bit
0xFFF20304 ADCA0ADCRL 16-bit
0xFFF20304 ADCA0ADCRLL
0xFFF20308 ADCA0SGSTR 32-bit ro
0xFFF20308 ADCA0SGSTRL 16-bit ro
0xFFF2030C ADCA0MPXCURR 32-bit ro
0xFFF2030C ADCA0MPXCURRL 16-bit ro
0xFFF2030C ADCA0MPXCURRLL ro
0xFFF20314 ADCA0THSMPSTCR 32-bit wo
0xFFF20314 ADCA0THSMPSTCRL 16-bit wo
0xFFF20314 ADCA0THSMPSTCRLL wo
0xFFF20318 ADCA0THCR 32-bit
0xFFF20318 ADCA0THCRL 16-bit
0xFFF20318 ADCA0THCRLL
0xFFF2031C ADCA0THAHLDSTCR 32-bit wo
0xFFF2031C ADCA0THAHLDSTCRL 16-bit wo
0xFFF2031C ADCA0THAHLDSTCRLL wo
0xFFF20320 ADCA0THBHLDSTCR 32-bit wo
0xFFF20320 ADCA0THBHLDSTCRL 16-bit wo
0xFFF20320 ADCA0THBHLDSTCRLL wo
0xFFF20324 ADCA0THACR 32-bit
0xFFF20324 ADCA0THACRL 16-bit
0xFFF20324 ADCA0THACRLL
0xFFF20328 ADCA0THBCR 32-bit
0xFFF20328 ADCA0THBCRL 16-bit
0xFFF20328 ADCA0THBCRLL
0xFFF2032C ADCA0THER 32-bit
0xFFF2032C ADCA0THERL 16-bit
0xFFF2032C ADCA0THERLL
0xFFF20330 ADCA0THGSR 32-bit
0xFFF20330 ADCA0THGSRL 16-bit
0xFFF20330 ADCA0THGSRLL
0xFFF20334 ADCA0SFTCR 32-bit
0xFFF20334 ADCA0SFTCRL 16-bit
0xFFF20334 ADCA0SFTCRLL
{0xFFF20338+4i} ADCA0ULLMTBR{i} 32-bit (i=0..2)
{0xFFF20338+4i} ADCA0ULLMTBR{i}L 16-bit (i=0..2)
{0xFFF2033A+4i} ADCA0ULLMTBR{i}H 16-bit (i=0..2)
0xFFF20344 ADCA0ECR 32-bit wo
0xFFF20344 ADCA0ECRL 16-bit wo
0xFFF20344 ADCA0ECRLL wo
0xFFF20348 ADCA0ULER 32-bit ro
0xFFF20348 ADCA0ULERL 16-bit ro
0xFFF20348 ADCA0ULERLL ro
0xFFF20349 ADCA0ULERLH ro
0xFFF2034C ADCA0OWER 32-bit ro
0xFFF2034C ADCA0OWERL 16-bit ro
0xFFF2034C ADCA0OWERLL ro
0xFFF20350 ADCA0DGCTL0 32-bit
0xFFF20350 ADCA0DGCTL0L 16-bit
0xFFF20350 ADCA0DGCTL0LL
0xFFF20354 ADCA0DGCTL1 32-bit
0xFFF20354 ADCA0DGCTL1L 16-bit
0xFFF20358 ADCA0PDCTL1 32-bit
0xFFF20358 ADCA0PDCTL1L 16-bit
0xFFF2035C ADCA0PDCTL2 32-bit
0xFFF2035C ADCA0PDCTL2L 16-bit
0xFFF2035C ADCA0PDCTL2LL
0xFFF2035D ADCA0PDCTL2LH
0xFFF2035E ADCA0PDCTL2H 16-bit
0xFFF2035E ADCA0PDCTL2HL
0xFFF20380 ADCA0SMPCR 32-bit
0xFFF20380 ADCA0SMPCRL 16-bit
0xFFF20380 ADCA0SMPCRLL
0xFFF20388 ADCA0EMU
{0xFFF20400+0x40*i} ADCA0SGSTCR{i} 32-bit wo (i=1..3)
{0xFFF20400+0x40*i} ADCA0SGSTCR{i}L 16-bit wo (i=1..3)
{0xFFF20400+0x40*i} ADCA0SGSTCR{i}LL wo (i=1..3)
{0xFFF20408+0x40*i} ADCA0SGCR{i} 32-bit (i=1..3)
{0xFFF20408+0x40*i} ADCA0SGCR{i}L 16-bit (i=1..3)
{0xFFF20408+0x40*i} ADCA0SGCR{i}LL (i=1..3)
{0xFFF2040C+0x40*i} ADCA0SGVCSP{i} 32-bit (i=1..3)
{0xFFF2040C+0x40*i} ADCA0SGVCSP{i}L 16-bit (i=1..3)
{0xFFF2040C+0x40*i} ADCA0SGVCSP{i}LL (i=1..3)
{0xFFF20410+0x40*i} ADCA0SGVCEP{i} 32-bit (i=1..3)
{0xFFF20410+0x40*i} ADCA0SGVCEP{i}L 16-bit (i=1..3)
{0xFFF20410+0x40*i} ADCA0SGVCEP{i}LL (i=1..3)
{0xFFF20414+0x40*i} ADCA0SGMCYCR{i} 32-bit (i=1..3)
{0xFFF20414+0x40*i} ADCA0SGMCYCR{i}L 16-bit (i=1..3)
{0xFFF20414+0x40*i} ADCA0SGMCYCR{i}LL (i=1..3)
{0xFFF20418+0x40*i} ADCA0SGSEFCR{i} 32-bit wo (i=1..3)
{0xFFF20418+0x40*i} ADCA0SGSEFCR{i}L 16-bit wo (i=1..3)
{0xFFF20418+0x40*i} ADCA0SGSEFCR{i}LL wo (i=1..3)
{0xFFF2041C+0x40*i} ADCA0SGTSEL{i} 32-bit (i=1..3)
{0xFFF2041C+0x40*i} ADCA0SGTSEL{i}L 16-bit (i=1..3)
0xFFF20508 ADCA0PWDSGCR 32-bit
0xFFF20508 ADCA0PWDSGCRL 16-bit
0xFFF20508 ADCA0PWDSGCRLL
0xFFF20518 ADCA0PWDSGSEFCR 32-bit wo
0xFFF20518 ADCA0PWDSGSEFCRL 16-bit wo
0xFFF20518 ADCA0PWDSGSEFCRLL wo
{0xFFF70000+0x1000*i} DCRA{i}CIN 32-bit (i=0..3)
{0xFFF70004+0x1000*i} DCRA{i}COUT 32-bit (i=0..3)
{0xFFF70020+0x1000*i} DCRA{i}CTL (i=0..3)
0xFFF78000 KR0KRM
  [n] KR0KRM{n} (n=0..7)
0xFFF80000 PROTCMD0 32-bit wo
0xFFF80004 PROTS0 32-bit ro
0xFFF80100 STBC0PSC 32-bit
0xFFF80110 STBC0STPT 32-bit
0xFFF80400 WUF0 32-bit ro
0xFFF80404 WUFMSK0 32-bit
0xFFF80408 WUFC0 32-bit wo
0xFFF80520 WUF20 32-bit ro
0xFFF80524 WUFMSK20 32-bit
0xFFF80528 WUFC20 32-bit wo
0xFFF80760 RESF 32-bit ro
0xFFF80768 RESFC 32-bit wo
0xFFF80860 RESFR 32-bit ro
0xFFF80868 RESFCR 32-bit wo
0xFFF80980 VLVF 32-bit ro
0xFFF80988 VLVFC 32-bit wo
0xFFF80A00 LVICNT 32-bit
0xFFF80A04 SWRESA 32-bit wo
0xFFF80B00 IOHOLD 32-bit
0xFFF81000 ROSCE 32-bit
0xFFF81004 ROSCS 32-bit ro
0xFFF81018 ROSCSTPM 32-bit
0xFFF81100 MOSCE 32-bit
0xFFF81104 MOSCS 32-bit ro
0xFFF81108 MOSCC 32-bit
0xFFF8110C MOSCST 32-bit
0xFFF81118 MOSCSTPM 32-bit
0xFFF81200 SOSCE 32-bit
0xFFF81204 SOSCS 32-bit ro
0xFFF8120C SOSCST 32-bit
0xFFF82800 FOUTDIV 32-bit
0xFFF82804 FOUTSTAT 32-bit ro
0xFFF83000 SCTLR 32-bit
0xFFF83004 EVFR 32-bit
0xFFF83008 DPSELR0 32-bit
0xFFF8300C DPSELRM 32-bit
0xFFF8300C DPSELRML 16-bit
{0xFFF8300B+i} DPSELR{i} (i=1..7)
0xFFF8300E DPSELRMH 16-bit
0xFFF83010 DPSELRH 32-bit
0xFFF83010 DPSELRHL 16-bit
0xFFF83012 DPSELRHH 16-bit
0xFFF83014 DPDSR0 32-bit
0xFFF83018 DPDSRM 32-bit
0xFFF83018 DPDSRML 16-bit
{0xFFF83017+i} DPDSR{i} (i=1..7)
0xFFF8301A DPDSRMH 16-bit
0xFFF8301C DPDSRH 32-bit
0xFFF8301C DPDSRHL 16-bit
0xFFF8301E DPDSRHH 16-bit
0xFFF83020 DPDIMR0 32-bit ro
{0xFFF83020+4i} DPDIMR{i} ro (i=1..7)
0xFFF83040 CNTVAL 16-bit
0xFFF83044 SOSTR ro
0xFFF83100 CVMF 32-bit
0xFFF83104 CVMDE 32-bit ro
0xFFF83114 CVMDIAG 32-bit
0xFFF83200 PROTCMDCVM 32-bit wo
0xFFF83204 PROTSCVM 32-bit ro
0xFFF88000 PROTCMD1 32-bit wo
0xFFF88004 PROTS1 32-bit ro
0xFFF88110 WUF_ISO0 32-bit ro
0xFFF88114 WUFMSK_ISO0 32-bit
0xFFF88118 WUFC_ISO0 32-bit wo
0xFFF89000 PLL0E 32-bit
0xFFF89004 PLL0S 32-bit ro
0xFFF89008 PLL0C 32-bit
0xFFF8900C PLL0ST 32-bit
0xFFF89100 PLL1E 32-bit
0xFFF89104 PLL1S 32-bit ro
0xFFF89108 PLL1C 32-bit
{0xFFF8C000+0x1000*i} CLMA{i}CTL0 (i=0..2)
{0xFFF8C008+0x1000*i} CLMA{i}CMPL 16-bit (i=0..2)
{0xFFF8C00C+0x1000*i} CLMA{i}CMPH 16-bit (i=0..2)
{0xFFF8C010+0x1000*i} CLMA{i}PCMD wo (i=0..2)
{0xFFF8C014+0x1000*i} CLMA{i}PS ro (i=0..2)
{0xFFF8C018+0x1000*i} CLMA{i}EMU0 (i=0..2)
0xFFF8C100 CLMATEST 32-bit
0xFFF8C104 CLMATESTS 32-bit ro
0xFFF8C200 PROTCMDCLMA 32-bit wo
0xFFF8C204 PROTSCLMA 32-bit ro
0xFFF90000 FSGD06PROT0 32-bit
0xFFF90000 FSGD06PROT0L 16-bit
0xFFF90000 FSGD06PROT0LL
0xFFF90001 FSGD06PROT0LH
0xFFF90002 FSGD06PROT0H 16-bit
0xFFF90002 FSGD06PROT0HL
0xFFF90003 FSGD06PROT0HH
0xFFF90004 FSGD06PROT1 32-bit
0xFFF90004 FSGD06PROT1L 16-bit
0xFFF90004 FSGD06PROT1LL
0xFFF90005 FSGD06PROT1LH
0xFFF90006 FSGD06PROT1H 16-bit
0xFFF90006 FSGD06PROT1HL
0xFFF90007 FSGD06PROT1HH
0xFFF90040 ERRSLV06CTL 32-bit wo
0xFFF90040 ERRSLV06CTLL 16-bit wo
0xFFF90040 ERRSLV06CTLLL wo
0xFFF90044 ERRSLV06STAT 32-bit ro
0xFFF90044 ERRSLV06STATL 16-bit ro
0xFFF90044 ERRSLV06STATLL ro
0xFFF9004C ERRSLV06TYPE 32-bit ro
0xFFF9004C ERRSLV06TYPEL 16-bit ro
{0xFFF94000+4i} FSGD03PROT{i} 32-bit (i=0..7)
{0xFFF94000+4i} FSGD03PROT{i}L 16-bit (i=0..7)
{0xFFF94000+4i} FSGD03PROT{i}LL (i=0..7)
{0xFFF94001+4i} FSGD03PROT{i}LH (i=0..7)
{0xFFF94002+4i} FSGD03PROT{i}H 16-bit (i=0..7)
{0xFFF94002+4i} FSGD03PROT{i}HL (i=0..7)
{0xFFF94003+4i} FSGD03PROT{i}HH (i=0..7)
{0xFFF94000+4i} FSGD03PROT{i} 32-bit (i=9..12)
{0xFFF94000+4i} FSGD03PROT{i}L 16-bit (i=9..12)
{0xFFF94000+4i} FSGD03PROT{i}LL (i=9..12)
{0xFFF94001+4i} FSGD03PROT{i}LH (i=9..12)
{0xFFF94002+4i} FSGD03PROT{i}H 16-bit (i=9..12)
{0xFFF94002+4i} FSGD03PROT{i}HL (i=9..12)
{0xFFF94003+4i} FSGD03PROT{i}HH (i=9..12)
{0xFFF93D40+0x100*i} ERRSLV{i:02}CTL 32-bit wo (i=3..5)
{0xFFF93D40+0x100*i} ERRSLV{i:02}CTLL 16-bit wo (i=3..5)
{0xFFF93D40+0x100*i} ERRSLV{i:02}CTLLL wo (i=3..5)
{0xFFF93D44+0x100*i} ERRSLV{i:02}STAT 32-bit ro (i=3..5)
{0xFFF93D44+0x100*i} ERRSLV{i:02}STATL 16-bit ro (i=3..5)
{0xFFF93D44+0x100*i} ERRSLV{i:02}STATLL ro (i=3..5)
{0xFFF93D4C+0x100*i} ERRSLV{i:02}TYPE 32-bit ro (i=3..5)
{0xFFF93D4C+0x100*i} ERRSLV{i:02}TYPEL 16-bit ro (i=3..5)
{0xFFF94100+4i} FSGD04PROT{i} 32-bit (i=0..3)
{0xFFF94100+4i} FSGD04PROT{i}L 16-bit (i=0..3)
{0xFFF94100+4i} FSGD04PROT{i}LL (i=0..3)
{0xFFF94101+4i} FSGD04PROT{i}LH (i=0..3)
{0xFFF94102+4i} FSGD04PROT{i}H 16-bit (i=0..3)
{0xFFF94102+4i} FSGD04PROT{i}HL (i=0..3)
{0xFFF94103+4i} FSGD04PROT{i}HH (i=0..3)
{0xFFF94200+4i} FSGD05PROT{i} 32-bit (i=0..15)
{0xFFF94200+4i} FSGD05PROT{i}L 16-bit (i=0..15)
{0xFFF94200+4i} FSGD05PROT{i}LL (i=0..15)
{0xFFF94201+4i} FSGD05PROT{i}LH (i=0..15)
{0xFFF94202+4i} FSGD05PROT{i}H 16-bit (i=0..15)
{0xFFF94202+4i} FSGD05PROT{i}HL (i=0..15)
{0xFFF94203+4i} FSGD05PROT{i}HH (i=0..15)
0xFFF9C000 HFSGD00PROT0 32-bit
0xFFF9C000 HFSGD00PROT0L 16-bit
0xFFF9C000 HFSGD00PROT0LL
0xFFF9C001 HFSGD00PROT0LH
0xFFF9C002 HFSGD00PROT0H 16-bit
0xFFF9C002 HFSGD00PROT0HL
0xFFF9C003 HFSGD00PROT0HH
0xFFF9C040 HERRSLV00CTL 32-bit wo
0xFFF9C040 HERRSLV00CTLL 16-bit wo
0xFFF9C040 HERRSLV00CTLLL wo
0xFFF9C044 HERRSLV00STAT 32-bit ro
0xFFF9C044 HERRSLV00STATL 16-bit ro
0xFFF9C044 HERRSLV00STATLL ro
0xFFF9C04C HERRSLV00TYPE 32-bit ro
0xFFF9C04C HERRSLV00TYPEL 16-bit ro
0xFFFEE002 IPGECRUM 16-bit
0xFFFEE008 IPGADRUM 32-bit
0xFFFEE00D IPGENUM
{0xFFFEE020+i} IPGPMTUM{i} (i=0..4)
0xFFFEE040 IPG0ECR 16-bit
0xFFFEE042 IPG0ECRUM 16-bit
0xFFFEE044 IPG0ADR 32-bit
0xFFFEE048 IPG0ADRUM 32-bit
0xFFFEE04C IPG0EN
0xFFFEE04D IPG0ENUM
{0xFFFEE050+i} IPG0PMT{i} (i=0..4)
{0xFFFEE060+i} IPG0PMTUM{i} (i=0..4)
0xFFFEE60C PEGSP 16-bit
0xFFFEE60C PEGSPL
{0xFFFEE680+0x10*i} PEGG{i}MK 32-bit (i=0..3)
{0xFFFEE680+0x10*i} PEGG{i}MKL 16-bit (i=0..3)
{0xFFFEE681+0x10*i} PEGG{i}MKLH (i=0..3)
{0xFFFEE682+0x10*i} PEGG{i}MKH 16-bit (i=0..3)
{0xFFFEE682+0x10*i} PEGG{i}MKHL (i=0..3)
{0xFFFEE683+0x10*i} PEGG{i}MKHH (i=0..3)
{0xFFFEE684+0x10*i} PEGG{i}BA 32-bit (i=0..3)
{0xFFFEE684+0x10*i} PEGG{i}BAL 16-bit (i=0..3)
{0xFFFEE684+0x10*i} PEGG{i}BALL (i=0..3)
{0xFFFEE685+0x10*i} PEGG{i}BALH (i=0..3)
{0xFFFEE686+0x10*i} PEGG{i}BAH 16-bit (i=0..3)
{0xFFFEE686+0x10*i} PEGG{i}BAHL (i=0..3)
{0xFFFEE687+0x10*i} PEGG{i}BAHH (i=0..3)
0xFFFEE980 SEGCONT 16-bit
0xFFFEE982 SEGFLAG 16-bit
{0xFFFEEA00+2i} ICIPIR{i} 16-bit (i=0..3)
{0xFFFEEA00+2i} ICIPIR{i}L (i=0..3)
  [7] MKIPIR{i}, [6] TBIPIR{i}, [n] P{n}IPIR{i} (n=0..3)
{0xFFFEEA01+2i} ICIPIR{i}H (i=0..3)
  [7] CTIPIR{i} ro, [4] RFIPIR{i}
0xFFFEEA08 ICBN0 16-bit
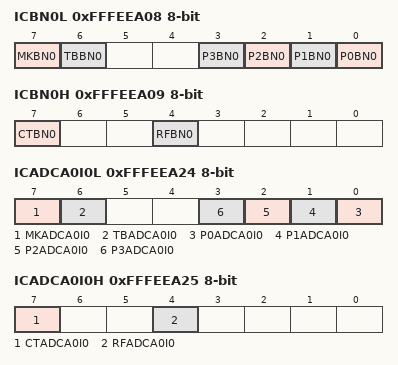
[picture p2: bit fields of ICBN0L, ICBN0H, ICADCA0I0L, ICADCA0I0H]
0xFFFEEA08 ICBN0L
  [7] MKBN0, [6] TBBN0, [n] P{n}BN0 (n=0..3)
0xFFFEEA09 ICBN0H
  [7] CTBN0 ro, [4] RFBN0
0xFFFEEA10 ICTAUD0I0 16-bit
0xFFFEEA10 ICTAUD0I0L
  [7] MKCSIH2IC_1, [7] MKTAUD0I0, [6] TBCSIH2IC_1, [6] TBTAUD0I0, [n] P{n}CSIH2IC_1 (n=0..3), [n] P{n}TAUD0I0 (n=0..3)
0xFFFEEA10 ICCSIH2IC_1 16-bit
0xFFFEEA10 ICCSIH2ICL_1
0xFFFEEA11 ICTAUD0I0H
  [7] CTCSIH2IC_1 ro, [7] CTTAUD0I0 ro, [4] RFCSIH2IC_1, [4] RFTAUD0I0
0xFFFEEA11 ICCSIH2ICH_1
0xFFFEEA12 ICTAUD0I2 16-bit
0xFFFEEA12 ICTAUD0I2L
  [7] MKCSIH3IC_1, [7] MKTAUD0I2, [6] TBCSIH3IC_1, [6] TBTAUD0I2, [n] P{n}CSIH3IC_1 (n=0..3), [n] P{n}TAUD0I2 (n=0..3)
0xFFFEEA12 ICCSIH3IC_1 16-bit
0xFFFEEA12 ICCSIH3ICL_1
0xFFFEEA13 ICTAUD0I2H
  [7] CTCSIH3IC_1 ro, [7] CTTAUD0I2 ro, [4] RFCSIH3IC_1, [4] RFTAUD0I2
0xFFFEEA13 ICCSIH3ICH_1
0xFFFEEA14 ICTAUD0I4 16-bit
0xFFFEEA14 ICTAUD0I4L
  [7] MKCSIH2IR_1, [7] MKTAUD0I4, [6] TBCSIH2IR_1, [6] TBTAUD0I4, [n] P{n}CSIH2IR_1 (n=0..3), [n] P{n}TAUD0I4 (n=0..3)
0xFFFEEA14 ICCSIH2IR_1 16-bit
0xFFFEEA14 ICCSIH2IRL_1
0xFFFEEA15 ICTAUD0I4H
  [7] CTCSIH2IR_1 ro, [7] CTTAUD0I4 ro, [4] RFCSIH2IR_1, [4] RFTAUD0I4
0xFFFEEA15 ICCSIH2IRH_1
0xFFFEEA16 ICTAUD0I6 16-bit
0xFFFEEA16 ICTAUD0I6L
  [7] MKCSIH2IRE_1, [7] MKTAUD0I6, [6] TBCSIH2IRE_1, [6] TBTAUD0I6, [n] P{n}CSIH2IRE_1 (n=0..3), [n] P{n}TAUD0I6 (n=0..3)
0xFFFEEA16 ICCSIH2IRE_1 16-bit
0xFFFEEA16 ICCSIH2IREL_1
0xFFFEEA17 ICTAUD0I6H
  [7] CTCSIH2IRE_1 ro, [7] CTTAUD0I6 ro, [4] RFCSIH2IRE_1, [4] RFTAUD0I6
0xFFFEEA17 ICCSIH2IREH_1
0xFFFEEA18 ICTAUD0I8 16-bit
0xFFFEEA18 ICTAUD0I8L
  [7] MKCSIH2IJC_1, [7] MKTAUD0I8, [6] TBCSIH2IJC_1, [6] TBTAUD0I8, [n] P{n}CSIH2IJC_1 (n=0..3), [n] P{n}TAUD0I8 (n=0..3)
0xFFFEEA18 ICCSIH2IJC_1 16-bit
0xFFFEEA18 ICCSIH2IJCL_1
0xFFFEEA19 ICTAUD0I8H
  [7] CTCSIH2IJC_1 ro, [7] CTTAUD0I8 ro, [4] RFCSIH2IJC_1, [4] RFTAUD0I8
0xFFFEEA19 ICCSIH2IJCH_1
0xFFFEEA1A ICTAUD0I10 16-bit
0xFFFEEA1A ICTAUD0I10L
  [7] MKCSIH3IR_1, [7] MKTAUD0I10, [6] TBCSIH3IR_1, [6] TBTAUD0I10, [n] P{n}CSIH3IR_1 (n=0..3), [n] P{n}TAUD0I10 (n=0..3)
0xFFFEEA1A ICCSIH3IR_1 16-bit
0xFFFEEA1A ICCSIH3IRL_1
0xFFFEEA1B ICTAUD0I10H
  [7] CTCSIH3IR_1 ro, [7] CTTAUD0I10 ro, [4] RFCSIH3IR_1, [4] RFTAUD0I10
0xFFFEEA1B ICCSIH3IRH_1
0xFFFEEA1C ICTAUD0I12 16-bit
0xFFFEEA1C ICTAUD0I12L
  [7] MKCSIH3IRE_1, [7] MKTAUD0I12, [6] TBCSIH3IRE_1, [6] TBTAUD0I12, [n] P{n}CSIH3IRE_1 (n=0..3), [n] P{n}TAUD0I12 (n=0..3)
0xFFFEEA1C ICCSIH3IRE_1 16-bit
0xFFFEEA1C ICCSIH3IREL_1
0xFFFEEA1D ICTAUD0I12H
  [7] CTCSIH3IRE_1 ro, [7] CTTAUD0I12 ro, [4] RFCSIH3IRE_1, [4] RFTAUD0I12
0xFFFEEA1D ICCSIH3IREH_1
0xFFFEEA1E ICTAUD0I14 16-bit
0xFFFEEA1E ICTAUD0I14L
  [7] MKCSIH3IJC_1, [7] MKTAUD0I14, [6] TBCSIH3IJC_1, [6] TBTAUD0I14, [n] P{n}CSIH3IJC_1 (n=0..3), [n] P{n}TAUD0I14 (n=0..3)
0xFFFEEA1E ICCSIH3IJC_1 16-bit
0xFFFEEA1E ICCSIH3IJCL_1
0xFFFEEA1F ICTAUD0I14H
  [7] CTCSIH3IJC_1 ro, [7] CTTAUD0I14 ro, [4] RFCSIH3IJC_1, [4] RFTAUD0I14
0xFFFEEA1F ICCSIH3IJCH_1
0xFFFEEA20 ICTAPA0IPEK0 16-bit
0xFFFEEA20 ICTAPA0IPEK0L
  [7] MKCSIH1IC_1, [7] MKTAPA0IPEK0, [6] TBCSIH1IC_1, [6] TBTAPA0IPEK0, [n] P{n}CSIH1IC_1 (n=0..3), [n] P{n}TAPA0IPEK0 (n=0..3)
0xFFFEEA20 ICCSIH1IC_1 16-bit
0xFFFEEA20 ICCSIH1ICL_1
0xFFFEEA21 ICTAPA0IPEK0H
  [7] CTCSIH1IC_1 ro, [7] CTTAPA0IPEK0 ro, [4] RFCSIH1IC_1, [4] RFTAPA0IPEK0
0xFFFEEA21 ICCSIH1ICH_1
0xFFFEEA22 ICTAPA0IVLY0 16-bit
0xFFFEEA22 ICTAPA0IVLY0L
  [7] MKCSIH1IR_1, [7] MKTAPA0IVLY0, [6] TBCSIH1IR_1, [6] TBTAPA0IVLY0, [n] P{n}CSIH1IR_1 (n=0..3), [n] P{n}TAPA0IVLY0 (n=0..3)
0xFFFEEA22 ICCSIH1IR_1 16-bit
0xFFFEEA22 ICCSIH1IRL_1
0xFFFEEA23 ICTAPA0IVLY0H
  [7] CTCSIH1IR_1 ro, [7] CTTAPA0IVLY0 ro, [4] RFCSIH1IR_1, [4] RFTAPA0IVLY0
0xFFFEEA23 ICCSIH1IRH_1
{0xFFFEEA24+2i} ICADCA0I{i} 16-bit (i=0..2)
0xFFFEEA24 ICADCA0I0L
  [7] MKADCA0I0, [6] TBADCA0I0, [n] P{n}ADCA0I0 (n=0..3)
0xFFFEEA25 ICADCA0I0H
  [7] CTADCA0I0 ro, [4] RFADCA0I0
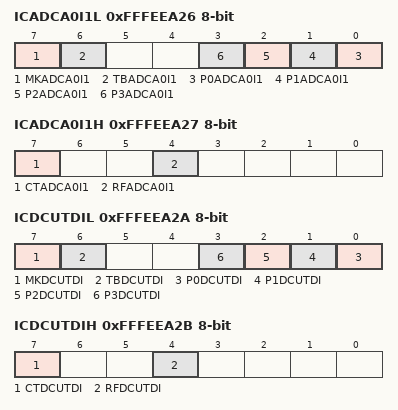
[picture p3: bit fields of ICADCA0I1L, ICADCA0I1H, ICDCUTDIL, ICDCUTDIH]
0xFFFEEA26 ICADCA0I1L
  [7] MKADCA0I1, [6] TBADCA0I1, [n] P{n}ADCA0I1 (n=0..3)
0xFFFEEA27 ICADCA0I1H
  [7] CTADCA0I1 ro, [4] RFADCA0I1
0xFFFEEA28 ICADCA0I2L
0xFFFEEA28 ICCSIH0IJC_1 16-bit
0xFFFEEA28 ICCSIH0IJCL_1
  [7] MKADCA0I2, [7] MKCSIH0IJC_1, [6] TBADCA0I2, [6] TBCSIH0IJC_1, [n] P{n}ADCA0I2 (n=0..3), [n] P{n}CSIH0IJC_1 (n=0..3)
0xFFFEEA29 ICADCA0I2H
0xFFFEEA29 ICCSIH0IJCH_1
  [7] CTADCA0I2 ro, [7] CTCSIH0IJC_1 ro, [4] RFADCA0I2, [4] RFCSIH0IJC_1
0xFFFEEA2A ICDCUTDI 16-bit
0xFFFEEA2A ICDCUTDIL
  [7] MKDCUTDI, [6] TBDCUTDI, [n] P{n}DCUTDI (n=0..3)
0xFFFEEA2B ICDCUTDIH
  [7] CTDCUTDI ro, [4] RFDCUTDI
0xFFFEEA2C ICRCANGERR0 16-bit
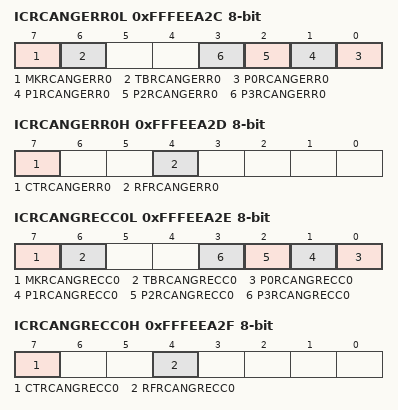
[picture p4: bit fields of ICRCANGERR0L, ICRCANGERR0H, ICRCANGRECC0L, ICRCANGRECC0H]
0xFFFEEA2C ICRCANGERR0L
  [7] MKRCANGERR0, [6] TBRCANGERR0, [n] P{n}RCANGERR0 (n=0..3)
0xFFFEEA2D ICRCANGERR0H
  [7] CTRCANGERR0 ro, [4] RFRCANGERR0
0xFFFEEA2E ICRCANGRECC0 16-bit
0xFFFEEA2E ICRCANGRECC0L
  [7] MKRCANGRECC0, [6] TBRCANGRECC0, [n] P{n}RCANGRECC0 (n=0..3)
0xFFFEEA2F ICRCANGRECC0H
  [7] CTRCANGRECC0 ro, [4] RFRCANGRECC0
0xFFFEEA30 ICRCAN0ERR 16-bit
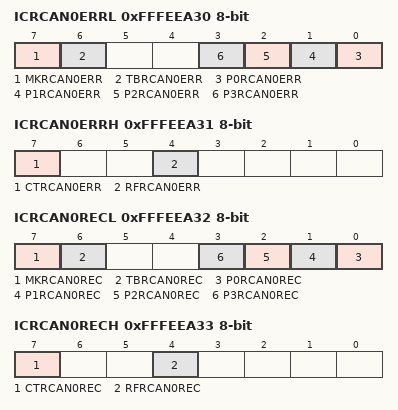
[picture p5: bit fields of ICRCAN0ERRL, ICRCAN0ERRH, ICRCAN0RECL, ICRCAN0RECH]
0xFFFEEA30 ICRCAN0ERRL
  [7] MKRCAN0ERR, [6] TBRCAN0ERR, [n] P{n}RCAN0ERR (n=0..3)
0xFFFEEA31 ICRCAN0ERRH
  [7] CTRCAN0ERR ro, [4] RFRCAN0ERR
0xFFFEEA32 ICRCAN0REC 16-bit
0xFFFEEA32 ICRCAN0RECL
  [7] MKRCAN0REC, [6] TBRCAN0REC, [n] P{n}RCAN0REC (n=0..3)
0xFFFEEA33 ICRCAN0RECH
  [7] CTRCAN0REC ro, [4] RFRCAN0REC
0xFFFEEA34 ICRCAN0TRX 16-bit
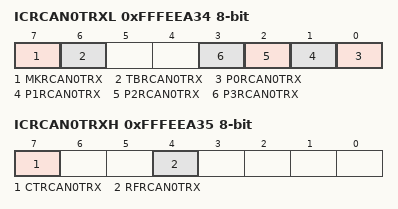
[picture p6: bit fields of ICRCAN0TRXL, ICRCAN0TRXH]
0xFFFEEA34 ICRCAN0TRXL
  [7] MKRCAN0TRX, [6] TBRCAN0TRX, [n] P{n}RCAN0TRX (n=0..3)
0xFFFEEA35 ICRCAN0TRXH
  [7] CTRCAN0TRX ro, [4] RFRCAN0TRX
0xFFFEEA36 ICCSIG0IC 16-bit
0xFFFEEA36 ICCSIG0ICL
0xFFFEEA36 ICCSIH1IRE_1 16-bit
0xFFFEEA36 ICCSIH1IREL_1
  [7] MKCSIG0IC, [7] MKCSIH1IRE_1, [6] TBCSIG0IC, [6] TBCSIH1IRE_1, [n] P{n}CSIG0IC (n=0..3), [n] P{n}CSIH1IRE_1 (n=0..3)
0xFFFEEA37 ICCSIG0ICH

## Notices in the file
Copyright(C) 2014 Renesas
